# MEC1322 register map
Vendor: Microchip Technology Inc.; Series: ARMCM4F; File version: 1.0
CPU: CM4 r1p0, little endian, MPU, FPU, 3 interrupt priority bits
Registers are 32-bit, read-write, reset 0x0 unless marked. A register's access mark holds for its fields unless they carry their own. Offsets are from the block's base; [hi:lo] are bit positions; lines under a group give offsets from that group; {n}, {i} and the like mark numbered series.

## VBAT — The VBAT Register Bank block is a block implemented for aggregating miscellaneous battery-backed registers required the host and by the Embedded Controller (EC) Subsystem that are not unique to a block implemented in the EC subsystem. . The VBAT Powered RAM provides a 64 Byte Random Accessed Memory that is operational while the main power rail is operational, and will retain its values powered by battery power while the main rail is unpowered.
Base 0x4000A400
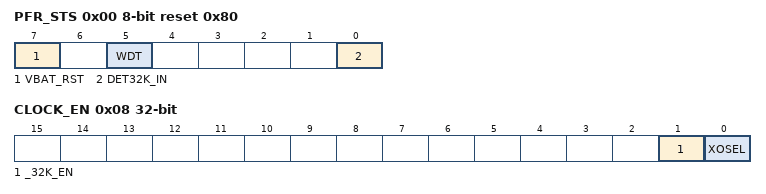
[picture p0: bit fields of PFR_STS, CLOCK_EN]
0x00 PFR_STS 8-bit reset 0x80 — The Power-Fail and Reset Status Register collects and retains the VBAT RST and WDT event status when VCC1 is unpowered.
  [7] VBAT_RST — The VBAT RST bit is set to '1' by hardware when a VBAT_POR is detected.(R/WC)
  [5] WDT — The WDT bit is asserted ('1') following a Watch-Dog Timer Forced Reset (WDT Event). To clear the WDT bit EC firmware must write a '1' to this bit; writing a '0' to the WDT bit has no affect.
  [0] DET32K_IN — 0 = No clock detected on the XTAL[1:2] pins. 1= Clock detected on the XTAL[1:2] pins.
0x08 CLOCK_EN — CLOCK ENABLE Control
  [1] _32K_EN — 0: 32.768 KHz Crystal Oscillator OFF (VBAT_POR default). 1: 32.768 KHz Crystal Oscillator ON. The 32.768 KHz Crystal Oscillator can only be enabled by firmware
  [0] XOSEL — This bit controls whether a crystal or single ended clock source is used. 1= the 32.768 KHz Crystal Oscillator is driven by a single-ended 32.768 KHz clock source connected to the XTAL2 pin. 0= the 32.768 KHz Crystal Oscillator requires a 32.768 KHz parallel resonant crystal connected between the XTAL1 and XTAL2 pins (default).

## GCR — The Logical Device Configuration registers support motherboard designs in which the resources required by their components are known and assigned by the BIOS at POST.
Base 0x400FFF00
0x07 LOGICAL_DEVICE_NUMBER 8-bit — A write to this register selects the current logical device. This allows access to the control and configuration registers for each logical device.
0x20 DEVICE_ID 8-bit read reset 0x15 — A read-only register which provides device identification.
0x21 DEVICE_REVISION 8-bit read — A read-only register which provides device revision information.

## ACPI — The ACPI Embedded Controller Interface (ACPI-ECI) provides a four byte full duplex data interface which is a superset of the standard ACPI Embedded Controller Interface (ACPI-ECI) one byte data interface. The ACPI Embedded Controller Interface (ACPI-ECI) defaults to the standard one byte interface.
Base 0x400F0C00
{0x0+0x400*i} EC[{i}] (i=0..1) group — Runtime Register Aliasing into EC-Only Registers indicates the aliasing from Runtime registers to EC-Only registers. The Host/EC Access column distinguishes the aliasing based on access type.
  {0x0+j} OS_DATA[{j}] (j=0..3) 8-bit — Writes by the ACPI_OS to the ACPI-OS DATA BYTES[n] are aliased to the OS2EC DATA BYTES[n]. Reads by the ACPI_OS from the ACPI-OS DATA BYTES[n] are aliased to the EC2OS DATA BYTES[n].
  0x04 OS_COMMAND 8-bit write — Writes to the this register are aliased in the OS2EC Data EC Byte 0 Register. Writes to the this register also set the CMD and IBF bits in the OS STATUS OS Register
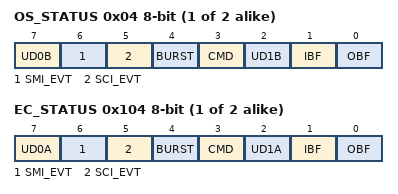
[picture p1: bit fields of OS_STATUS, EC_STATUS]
  0x04 OS_STATUS 8-bit read (alternate view of OS_COMMAND)
    [7] UD0B — UD0B User Defined
    [6] SMI_EVT — SMI_EVT This bit is set when an SMI event is pending
    [5] SCI_EVT — SCI_EVT This bit is set by software when an SCI event is pending
    [4] BURST — BURST The BURST bit is set when the ACPI_EC is in Burst Mode
    [3] CMD — CMD This bit is set when the OS2EC Data EC Byte 0 Register contains a command byte written into ACPI OS COMMAND Register
    [2] UD1B — UD1B User Defined
    [1] IBF — IBF The Input Buffer Full bit is set to indicate that a the ACPI_OS has written a command or data to the ACPI_EC and that data is ready.
    [0] OBF — OBF The Output Buffer Full bit is set to indicate that a the ACPI_EC has written a data to the ACPI_OS and that data is ready.
  0x05 OS_BYTE_CONTROL 8-bit read — OS Byte Control [0:0] FOUR_BYTE_ACCESS When this bit is set to '1', the ACPI Embedded Controller Interface (ACPI-ECI) accesses four bytes through the ACPI-OS DATA BYTES[3:0]. When this bit is cleared to '0', the ACPI Embedded Controller Interface (ACPI-ECI) accesses one byte through the ACPI OS Data Register Byte 0 Register.
  {0x100+j} EC2OS_DATA[{j}] (j=0..3) 8-bit — EC2OS Data Bytes
  0x104 EC_STATUS 8-bit
    [7] UD0A — UD0A User Defined
    [6] SMI_EVT — SMI_EVT This bit is set when an SMI event is pending
    [5] SCI_EVT — SCI_EVT This bit is set by software when an SCI event is pending
    [4] BURST — BURST The BURST bit is set when the ACPI_EC is in Burst Mode
    [3] CMD read — CMD This bit is set when the OS2EC Data EC Byte 0 Register contains a command byte written into ACPI OS COMMAND Register
    [2] UD1A read — UD1A User Defined
    [1] IBF read — IBF The Input Buffer Full bit is set to indicate that a the ACPI_OS has written a command or data to the ACPI_EC and that data is ready.
    [0] OBF read — OBF The Output Buffer Full bit is set to indicate that a the ACPI_EC has written a data to the ACPI_OS and that data is ready.
  0x105 EC_BYTE_CONTROL 8-bit reset 0xF — [0:0] FOUR_BYTE_ACCESS When this bit is set to '1', the ACPI Embedded Controller Interface (ACPI-ECI) accesses four bytes through the ACPI-OS DATA BYTES[3:0]. When this bit is cleared to '0', the ACPI Embedded Controller Interface (ACPI-ECI) accesses one byte through the ACPI OS Data Register Byte 0 Register.
  {0x108+j} OS2EC_DATA[{j}] (j=0..3) 8-bit — OS2EC Data Bytes
